# STM32U5xx register map
File version: 1.7
Registers are 32-bit, read-write, reset 0x0 unless marked. A register's access mark holds for its fields unless they carry their own. Offsets are from the block's base; [hi:lo] are bit positions; {n}, {i} and the like mark numbered series.

## AES — Advanced encryption standard hardware accelerator
Base 0x420C0000
Same registers: SEC_AES 0x520C0000
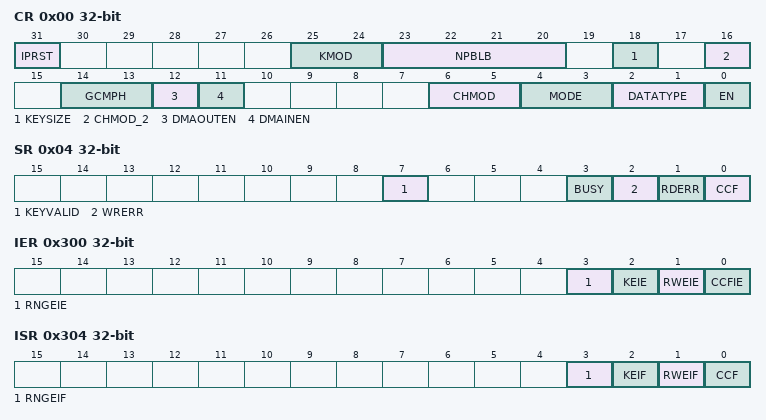
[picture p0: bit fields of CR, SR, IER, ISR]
0x00 CR — control register
  [31] IPRST
  [25:24] KMOD
  [23:20] NPBLB
  [18] KEYSIZE
  [16] CHMOD_2
  [14:13] GCMPH
  [12] DMAOUTEN — Enable DMA management of data output phase
  [11] DMAINEN — Enable DMA management of data input phase
  [6:5] CHMOD — AES chaining mode
  [4:3] MODE — AES operating mode
  [2:1] DATATYPE — Data type selection (for data in and data out to/from the cryptographic block)
  [0] EN — AES enable
0x04 SR ro — status register
  [7] KEYVALID — Key Valid flag
  [3] BUSY
  [2] WRERR — Write error flag
  [1] RDERR — Read error flag
  [0] CCF — Computation complete flag
0x08 DINR wo — data input register
  [31:0] DIN — Input data word
0x0C DOUTR ro — data output register
  [31:0] DOUT — Output data word
0x10 KEYR0 wo — key register 0
  [31:0] KEY — Cryptographic key, bits [31:0]
0x14 KEYR1 wo — key register 1
  [31:0] KEY — Cryptographic key, bits [63:32]
0x18 KEYR2 wo — key register 2
  [31:0] KEYR — Cryptographic key, bits [95:64]
0x1C KEYR3 wo — key register 3
  [31:0] AES_KEYR3 — Cryptographic key, bits [127:96]
{0x20+4i} IVR{i} (i=0..3) — initialization vector register {i}
  [31:0] IVI — Initialization vector input, bits [{32i+31}:{32i}]
{0x20+4i} KEYR{i} wo (i=4..7) — key register {i}
  [31:0] KEY — Cryptographic key, bits [{32i+31}:{32i}]
{0x40+4i} SUSP{i}R wo (i=0..7) — suspend registers
  [31:0] SUSP{i} — AES suspend
0x300 IER — interrupt enable register
  [3] RNGEIE — Key error interrupt flag
  [2] KEIE — Key error interrupt flag
  [1] RWEIE — Read or write error interrupt flag
  [0] CCFIE — Computation complete flag
0x304 ISR ro — interrupt status register
  [3] RNGEIF — Key error interrupt flag
  [2] KEIF — Key error interrupt flag
  [1] RWEIF — Read or write error interrupt flag
  [0] CCF — Computation complete flag
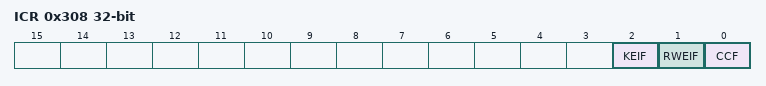
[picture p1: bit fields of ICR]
0x308 ICR wo — interrupt clear register
  [2] KEIF — Key error interrupt flag clear
  [1] RWEIF — Read or write error interrupt flag clear
  [0] CCF — Computation complete flag clear

## SAES — Secure AES coprocessor
Base 0x420C0C00
Same registers: SEC_SAES 0x520C0C00
Registers as AES (with AES read as SAES), without SUSP{n}R (n=0..7); these are added or differ:
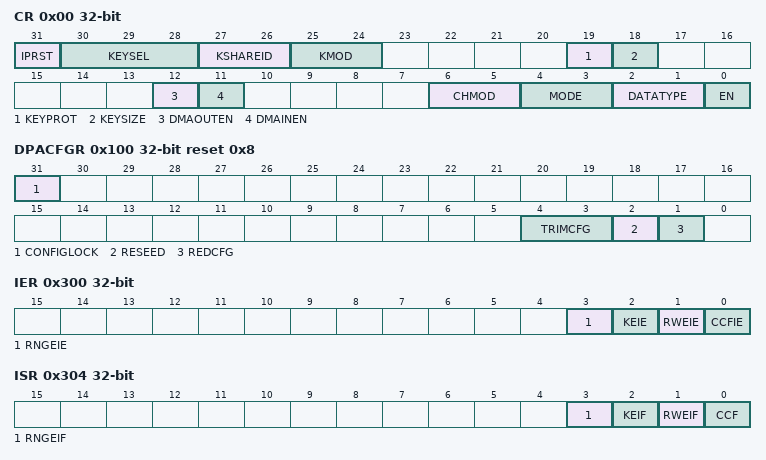
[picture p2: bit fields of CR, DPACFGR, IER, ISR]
0x00 CR — control register
  [31] IPRST
  [30:28] KEYSEL
  [27:26] KSHAREID
  [25:24] KMOD
  [19] KEYPROT
  [18] KEYSIZE
  [12] DMAOUTEN
  [11] DMAINEN
  [6:5] CHMOD
  [4:3] MODE
  [2:1] DATATYPE
  [0] EN — SAES enable
0x100 DPACFGR access per field reset 0x8 — configuration register
  [31] CONFIGLOCK ro, [4:3] TRIMCFG rw, [2] RESEED rw, [1] REDCFG rw
0x300 IER — interrupt enable register
  [3] RNGEIE
  [2] KEIE — Key error interrupt enable
  [1] RWEIE — Read or write error interrupt enable
  [0] CCFIE — Computation complete flag interrupt enable
0x304 ISR ro — interrupt status register
  [3] RNGEIF
  [2] KEIF — Key error interrupt flag
  [1] RWEIF — Read or write error interrupt flag
  [0] CCF — Computation complete flag
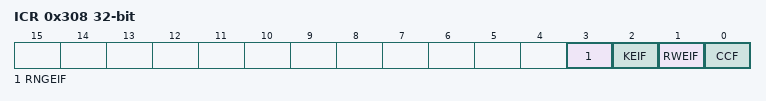
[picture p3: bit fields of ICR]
0x308 ICR wo — interrupt clear register
  [3] RNGEIF
  [2] KEIF — Key error interrupt flag clear
  [1] RWEIF — Read or write error interrupt flag clear
  [0] CCF — Computation complete flag clear

## FMAC — Filter Math Accelerator
Base 0x40021400
Same registers: SEC_FMAC 0x50021400
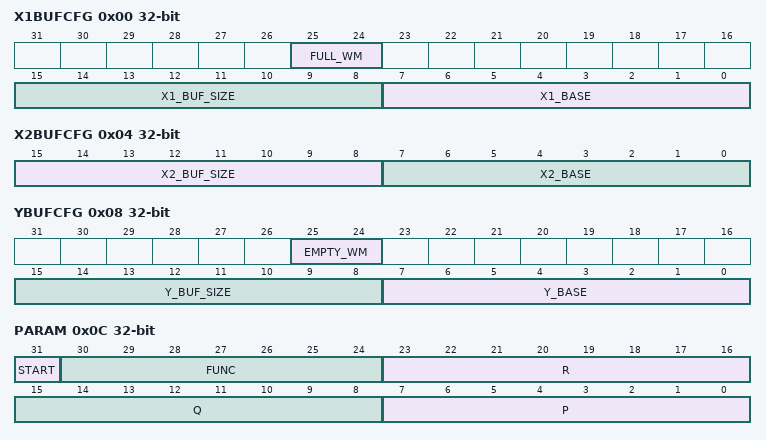
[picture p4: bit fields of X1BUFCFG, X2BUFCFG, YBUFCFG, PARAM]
0x00 X1BUFCFG — FMAC X1 Buffer Configuration register
  [25:24] FULL_WM — Watermark for buffer full flag
  [15:8] X1_BUF_SIZE — Allocated size of X1 buffer in 16-bit words
  [7:0] X1_BASE — Base address of X1 buffer
0x04 X2BUFCFG — FMAC X2 Buffer Configuration register
  [15:8] X2_BUF_SIZE — Size of X2 buffer in 16-bit words
  [7:0] X2_BASE — Base address of X2 buffer
0x08 YBUFCFG — FMAC Y Buffer Configuration register
  [25:24] EMPTY_WM — Watermark for buffer empty flag
  [15:8] Y_BUF_SIZE — Size of Y buffer in 16-bit words
  [7:0] Y_BASE — Base address of Y buffer
0x0C PARAM — FMAC Parameter register
  [31] START — Enable execution
  [30:24] FUNC — Function
  [23:16] R — Input parameter R
  [15:8] Q — Input parameter Q
  [7:0] P — Input parameter P
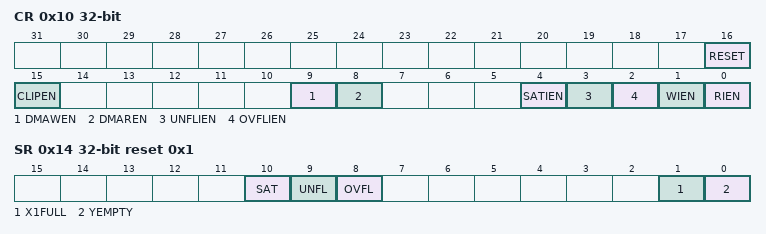
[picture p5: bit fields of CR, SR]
0x10 CR — FMAC Control register
  [16] RESET — Reset FMAC unit
  [15] CLIPEN — Enable clipping
  [9] DMAWEN — Enable DMA write channel requests
  [8] DMAREN — Enable DMA read channel requests
  [4] SATIEN — Enable saturation error interrupts
  [3] UNFLIEN — Enable underflow error interrupts
  [2] OVFLIEN — Enable overflow error interrupts
  [1] WIEN — Enable write interrupt
  [0] RIEN — Enable read interrupt
0x14 SR ro reset 0x1 — FMAC Status register
  [10] SAT — Saturation error flag
  [9] UNFL — Underflow error flag
  [8] OVFL — Overflow error flag
  [1] X1FULL — X1 buffer full flag
  [0] YEMPTY — Y buffer empty flag
0x18 WDATA wo — FMAC Write Data register
  [15:0] WDATA — Write data
0x1C RDATA ro — FMAC Read Data register
  [15:0] RDATA — Read data

## Notices in the file
Copyright (c) 2021 STMicroelectronics.
SPDX-License-Identifier: Apache-2.0
Licensed under the Apache License, Version 2.0 (the "License");
you may not use this file except in compliance with the License.
You may obtain a copy of the License at
http://www.apache.org/licenses/LICENSE-2.0
Unless required by applicable law or agreed to in writing, software
distributed under the License is distributed on an "AS IS" BASIS,
WITHOUT WARRANTIES OR CONDITIONS OF ANY KIND, either express or implied.
See the License for the specific language governing permissions and
limitations under the License.
